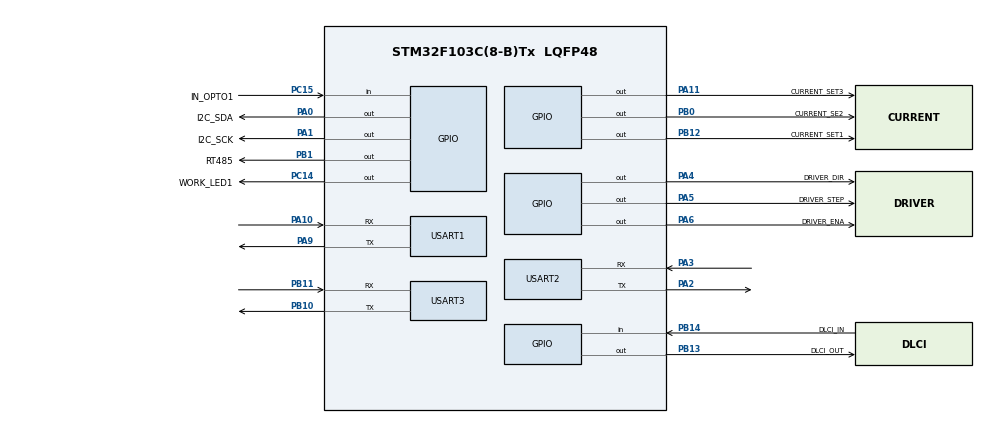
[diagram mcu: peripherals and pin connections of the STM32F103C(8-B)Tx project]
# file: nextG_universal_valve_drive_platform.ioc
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ADC1.Channel-0\#ChannelRegularConversion=ADC_CHANNEL_TEMPSENSOR
ADC1.NbrOfConversionFlag=1
ADC1.Rank-0\#ChannelRegularConversion=1
ADC1.SamplingTime-0\#ChannelRegularConversion=ADC_SAMPLETIME_1CYCLE_5
ADC1.master=1
Dma.Request0=USART1_RX
Dma.Request1=USART1_TX
Dma.Request2=USART2_RX
Dma.Request3=USART2_TX
Dma.Request4=USART3_RX
Dma.Request5=USART3_TX
Dma.USART1_RX.0.Direction=DMA_PERIPH_TO_MEMORY
Dma.USART1_RX.0.Instance=DMA1_Channel5
Dma.USART1_RX.0.MemDataAlignment=DMA_MDATAALIGN_BYTE
Dma.USART1_RX.0.MemInc=DMA_MINC_ENABLE
Dma.USART1_RX.0.Mode=DMA_NORMAL
Dma.USART1_RX.0.PeriphDataAlignment=DMA_PDATAALIGN_BYTE
Dma.USART1_RX.0.PeriphInc=DMA_PINC_DISABLE
Dma.USART1_RX.0.Priority=DMA_PRIORITY_LOW
Dma.USART1_TX.1.Direction=DMA_MEMORY_TO_PERIPH
Dma.USART1_TX.1.Instance=DMA1_Channel4
Dma.USART1_TX.1.MemDataAlignment=DMA_MDATAALIGN_BYTE
Dma.USART1_TX.1.MemInc=DMA_MINC_ENABLE
Dma.USART1_TX.1.Mode=DMA_NORMAL
Dma.USART1_TX.1.PeriphDataAlignment=DMA_PDATAALIGN_BYTE
Dma.USART1_TX.1.PeriphInc=DMA_PINC_DISABLE
Dma.USART1_TX.1.Priority=DMA_PRIORITY_LOW
Dma.USART2_RX.2.Direction=DMA_PERIPH_TO_MEMORY
Dma.USART2_RX.2.Instance=DMA1_Channel6
Dma.USART2_RX.2.MemDataAlignment=DMA_MDATAALIGN_BYTE
Dma.USART2_RX.2.MemInc=DMA_MINC_ENABLE
Dma.USART2_RX.2.Mode=DMA_NORMAL
Dma.USART2_RX.2.PeriphDataAlignment=DMA_PDATAALIGN_BYTE
Dma.USART2_RX.2.PeriphInc=DMA_PINC_DISABLE
Dma.USART2_RX.2.Priority=DMA_PRIORITY_LOW
Dma.USART2_TX.3.Direction=DMA_MEMORY_TO_PERIPH
Dma.USART2_TX.3.Instance=DMA1_Channel7
Dma.USART2_TX.3.MemDataAlignment=DMA_MDATAALIGN_BYTE
Dma.USART2_TX.3.MemInc=DMA_MINC_ENABLE
Dma.USART2_TX.3.Mode=DMA_NORMAL
Dma.USART2_TX.3.PeriphDataAlignment=DMA_PDATAALIGN_BYTE
Dma.USART2_TX.3.PeriphInc=DMA_PINC_DISABLE
Dma.USART2_TX.3.Priority=DMA_PRIORITY_LOW
Dma.USART3_RX.4.Direction=DMA_PERIPH_TO_MEMORY
Dma.USART3_RX.4.Instance=DMA1_Channel3
Dma.USART3_RX.4.MemDataAlignment=DMA_MDATAALIGN_BYTE
Dma.USART3_RX.4.MemInc=DMA_MINC_ENABLE
Dma.USART3_RX.4.Mode=DMA_NORMAL
Dma.USART3_RX.4.PeriphDataAlignment=DMA_PDATAALIGN_BYTE
Dma.USART3_RX.4.PeriphInc=DMA_PINC_DISABLE
Dma.USART3_RX.4.Priority=DMA_PRIORITY_LOW
Dma.USART3_TX.5.Direction=DMA_MEMORY_TO_PERIPH
Dma.USART3_TX.5.Instance=DMA1_Channel2
Dma.USART3_TX.5.MemDataAlignment=DMA_MDATAALIGN_BYTE
Dma.USART3_TX.5.MemInc=DMA_MINC_ENABLE
Dma.USART3_TX.5.Mode=DMA_NORMAL
Dma.USART3_TX.5.PeriphDataAlignment=DMA_PDATAALIGN_BYTE
Dma.USART3_TX.5.PeriphInc=DMA_PINC_DISABLE
Dma.USART3_TX.5.Priority=DMA_PRIORITY_LOW
IWDG.Prescaler=IWDG_PRESCALER_16
Mcu.Family=STM32F1
Mcu.Name=STM32F103C(8-B)Tx
Mcu.Package=LQFP48
NVIC.DMA1_Channel2_IRQn=true\:0\:0\:false\:false\:true\:false\:true\:true
NVIC.DMA1_Channel3_IRQn=true\:0\:0\:false\:false\:true\:false\:true\:true
NVIC.DMA1_Channel4_IRQn=true\:0\:0\:false\:false\:true\:false\:true\:true
NVIC.DMA1_Channel5_IRQn=true\:0\:0\:false\:false\:true\:false\:true\:true
NVIC.DMA1_Channel6_IRQn=true\:0\:0\:false\:false\:true\:false\:true\:true
NVIC.DMA1_Channel7_IRQn=true\:0\:0\:false\:false\:true\:false\:true\:true
NVIC.PriorityGroup=NVIC_PRIORITYGROUP_4
NVIC.USART1_IRQn=true\:0\:0\:false\:false\:true\:false\:true\:true
NVIC.USART2_IRQn=true\:0\:0\:false\:false\:true\:false\:true\:true
NVIC.USART3_IRQn=true\:0\:0\:false\:false\:true\:false\:true\:true
PA0-WKUP.GPIO_Label=I2C_SDA
PA0-WKUP.GPIO_PuPd=GPIO_PULLUP
PA0-WKUP.Signal=GPIO_Output
PA1.GPIO_Label=I2C_SCK
PA1.GPIO_PuPd=GPIO_PULLUP
PA1.Signal=GPIO_Output
PA10.Mode=Asynchronous
PA10.Signal=USART1_RX
PA11.GPIO_Label=CURRENT_SET3
PA11.Signal=GPIO_Output
PA13.Mode=Serial_Wire
PA13.Signal=SYS_JTMS-SWDIO
PA14.Mode=Serial_Wire
PA14.Signal=SYS_JTCK-SWCLK
PA2.Mode=Asynchronous
PA2.Signal=USART2_TX
PA3.Mode=Asynchronous
PA3.Signal=USART2_RX
PA4.GPIO_Label=DRIVER_DIR
PA4.Signal=GPIO_Output
PA5.GPIO_Label=DRIVER_STEP
PA5.Signal=GPIO_Output
PA6.GPIO_Label=DRIVER_ENA
PA6.Signal=GPIO_Output
PA9.Mode=Asynchronous
PA9.Signal=USART1_TX
PB0.GPIO_Label=CURRENT_SE2
PB0.Signal=GPIO_Output
PB1.GPIO_Label=RT485
PB1.Signal=GPIO_Output
PB10.Mode=Asynchronous
PB10.Signal=USART3_TX
PB11.Mode=Asynchronous
PB11.Signal=USART3_RX
PB12.GPIO_Label=CURRENT_SET1
PB12.Signal=GPIO_Output
PB13.GPIO_Label=DLCI_OUT
PB13.Signal=GPIO_Output
PB14.GPIO_Label=DLCI_IN
PB14.Signal=GPIO_Input
PC14-OSC32_IN.GPIO_Label=WORK_LED1
PC14-OSC32_IN.PinState=GPIO_PIN_SET
PC14-OSC32_IN.Signal=GPIO_Output
PC15-OSC32_OUT.GPIO_Label=IN_OPTO1
PC15-OSC32_OUT.Signal=GPIO_Input
PD0-OSC_IN.Mode=HSE-External-Oscillator
PD0-OSC_IN.Signal=RCC_OSC_IN
PD1-OSC_OUT.Mode=HSE-External-Oscillator
PD1-OSC_OUT.Signal=RCC_OSC_OUT
ProjectManager.HeapSize=0x200
ProjectManager.StackSize=0x400
ProjectManager.TargetToolchain=CMake
RCC.ADCPresc=RCC_ADCPCLK2_DIV6
RCC.AHBFreq_Value=72000000
RCC.APB1CLKDivider=RCC_HCLK_DIV2
RCC.APB1Freq_Value=36000000
RCC.APB1TimFreq_Value=72000000
RCC.APB2Freq_Value=72000000
RCC.APB2TimFreq_Value=72000000
RCC.HCLKFreq_Value=72000000
RCC.PLLMUL=RCC_PLL_MUL9
RCC.PLLSourceVirtual=RCC_PLLSOURCE_HSE
RCC.SYSCLKFreq_VALUE=72000000
RCC.SYSCLKSource=RCC_SYSCLKSOURCE_PLLCLK
RCC.USBFreq_Value=72000000
USART1.VirtualMode=VM_ASYNC
USART2.VirtualMode=VM_ASYNC
USART3.VirtualMode=VM_ASYNC
VP_ADC1_TempSens_Input.Mode=IN-TempSens
VP_CRC_VS_CRC.Mode=CRC_Activate
VP_IWDG_VS_IWDG.Mode=IWDG_Activate
VP_TIM1_VS_ClockSourceINT.Mode=Internal
VP_TIM2_VS_ClockSourceINT.Mode=Internal
VP_TIM3_VS_ClockSourceINT.Mode=Internal
VP_TIM4_VS_ClockSourceINT.Mode=Internal
board=custom

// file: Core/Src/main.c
/* USER CODE BEGIN Header */
/**
  ******************************************************************************
  * @file           : main.c
  * @brief          : Main program body
  ******************************************************************************
  * @attention
  *
  * Copyright (c) 2026 STMicroelectronics.
  * All rights reserved.
  *
  * This software is licensed under terms that can be found in the LICENSE file
  * in the root directory of this software component.
  * If no LICENSE file comes with this software, it is provided AS-IS.
  *
  ******************************************************************************
  */
/* USER CODE END Header */
#include "main.h"
#include "adc.h"
#include "crc.h"
#include "dma.h"
#include "iwdg.h"
#include "tim.h"
#include "usart.h"
#include "gpio.h"

/* USER CODE BEGIN Includes */
#include "app.h"
/* USER CODE END Includes */

void SystemClock_Config(void);

int main(void)
{

  /* MCU Configuration--------------------------------------------------------*/

  /* Reset of all peripherals, Initializes the Flash interface and the Systick. */
  LL_APB2_GRP1_EnableClock(LL_APB2_GRP1_PERIPH_AFIO);
  LL_APB1_GRP1_EnableClock(LL_APB1_GRP1_PERIPH_PWR);

  /* System interrupt init*/
  NVIC_SetPriorityGrouping(NVIC_PRIORITYGROUP_4);

  /* SysTick_IRQn interrupt configuration */
  NVIC_SetPriority(SysTick_IRQn, NVIC_EncodePriority(NVIC_GetPriorityGrouping(),15, 0));

  /** NOJTAG: JTAG-DP Disabled and SW-DP Enabled
  */
  LL_GPIO_AF_Remap_SWJ_NOJTAG();

  /* Configure the system clock */
  SystemClock_Config();

  /* Initialize all configured peripherals */
  MX_GPIO_Init();
  MX_DMA_Init();
  MX_TIM1_Init();
  MX_TIM2_Init();
  MX_TIM3_Init();
  MX_TIM4_Init();
  MX_USART1_UART_Init();
  MX_USART2_UART_Init();
  MX_USART3_UART_Init();
  MX_CRC_Init();
  // MX_IWDG_Init();
  MX_ADC1_Init();
  /* USER CODE BEGIN 2 */
  app_MainLoop();   /* 接管主循环 */
  /* USER CODE END 2 */

  /* Infinite loop */
  while (1)
  {

  }
}

void SystemClock_Config(void)
{
  LL_FLASH_SetLatency(LL_FLASH_LATENCY_2);
  while(LL_FLASH_GetLatency()!= LL_FLASH_LATENCY_2)
  {
  }
  LL_RCC_HSE_Enable();

   /* Wait till HSE is ready */
  while(LL_RCC_HSE_IsReady() != 1)
  {

  }
  LL_RCC_LSI_Enable();

   /* Wait till LSI is ready */
  while(LL_RCC_LSI_IsReady() != 1)
  {

  }
  LL_RCC_PLL_ConfigDomain_SYS(LL_RCC_PLLSOURCE_HSE_DIV_1, LL_RCC_PLL_MUL_9);
  LL_RCC_PLL_Enable();

   /* Wait till PLL is ready */
  while(LL_RCC_PLL_IsReady() != 1)
  {

  }
  LL_RCC_SetAHBPrescaler(LL_RCC_SYSCLK_DIV_1);
  LL_RCC_SetAPB1Prescaler(LL_RCC_APB1_DIV_2);
  LL_RCC_SetAPB2Prescaler(LL_RCC_APB2_DIV_1);
  LL_RCC_SetSysClkSource(LL_RCC_SYS_CLKSOURCE_PLL);

   /* Wait till System clock is ready */
  while(LL_RCC_GetSysClkSource() != LL_RCC_SYS_CLKSOURCE_STATUS_PLL)
  {

  }
  LL_Init1msTick(72000000);
  LL_SetSystemCoreClock(72000000);
  LL_RCC_SetADCClockSource(LL_RCC_ADC_CLKSRC_PCLK2_DIV_6);
}

void Error_Handler(void)
{
  __disable_irq();
  while (1)
  {
  }
}
